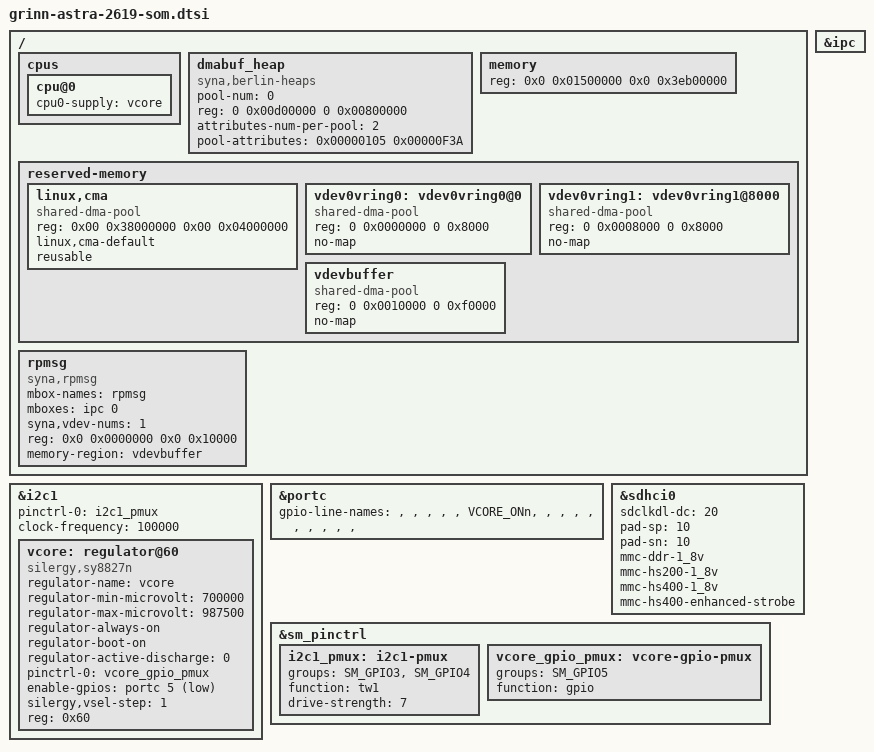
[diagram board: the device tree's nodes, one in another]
// SPDX-License-Identifier: (GPL-2.0 OR MIT)
/*
 * Copyright (C) 2025 Grinn
 */

#include <dt-bindings/gpio/gpio.h>

/ {
	cpus {
		cpu@0 {
			cpu0-supply = <&vcore>;
		};
	};

	dmabuf_heap {
		compatible = "syna,berlin-heaps";
		pool-num = <0>;
		reg-names = "NonSecure-NC";
		reg = <0 0x00d00000 0 0x00800000>;
		attributes-num-per-pool = <2>;
		pool-attributes = <0x00000105 0x00000F3A>;
	};

	memory {
		device_type = "memory";
		reg = <0x0 0x01500000 0x0 0x3eb00000>;
	};

	reserved-memory {
		#address-cells = <2>;
		#size-cells = <2>;
		ranges;

		linux,cma {
			compatible = "shared-dma-pool";
			reg = <0x00 0x38000000 0x00 0x04000000>;
			linux,cma-default;
			reusable;
		};

		vdev0vring0: vdev0vring0@0 {
			compatible = "shared-dma-pool";
			reg = <0 0x0000000 0 0x8000>;
			no-map;
		};

		vdev0vring1: vdev0vring1@8000 {
			compatible = "shared-dma-pool";
			reg = <0 0x0008000 0 0x8000>;
			no-map;
		};

		vdevbuffer: vdevbuffer {
			compatible = "shared-dma-pool";
			reg = <0 0x0010000 0 0xf0000>;
			no-map;
		};
	};

	rpmsg {
		compatible = "syna,rpmsg";
		mbox-names = "rpmsg";
		mboxes = <&ipc 0>;
		syna,vdev-nums = <1>;
		reg = <0x0 0x0000000 0x0 0x10000>;
		memory-region = <&vdevbuffer>;
	};
};

&i2c1 {
	status = "okay";
	pinctrl-names = "default";
	pinctrl-0 = <&i2c1_pmux>;
	clock-frequency = <100000>;

	vcore: regulator@60 {
		compatible = "silergy,sy8827n";
		regulator-name = "vcore";
		regulator-min-microvolt = <700000>;
		regulator-max-microvolt = <987500>;
		regulator-always-on;
		regulator-boot-on;
		regulator-active-discharge = <0>;
		pinctrl-names = "default";
		pinctrl-0 = <&vcore_gpio_pmux>;
		enable-gpios = <&portc 5 GPIO_ACTIVE_LOW>;
		silergy,vsel-step = <1>;
		reg = <0x60>;
	};
};

&ipc {
	status = "okay";
};

&portc {
	gpio-line-names =
		"", "", "", "", "", "VCORE_ONn", "", "",
		"", "", "", "", "", "", "", "";
};

&sdhci0 {
	status = "okay";
	sdclkdl-dc = /bits/ 8 <20>;
	pad-sp = /bits/ 8 <10>;
	pad-sn = /bits/ 8 <10>;
	mmc-ddr-1_8v;
	mmc-hs200-1_8v;
	mmc-hs400-1_8v;
	mmc-hs400-enhanced-strobe;
};

&sm_pinctrl {
	i2c1_pmux: i2c1-pmux {
		groups = "SM_GPIO3", "SM_GPIO4";
		function = "tw1";
		drive-strength = <7>;
	};

	vcore_gpio_pmux: vcore-gpio-pmux {
		groups = "SM_GPIO5";
		function = "gpio";
	};
};
